# ADSP-SC83xW_HPC register map
Vendor: Analog Devices; Series: ADSP-SC83xW_HPC; File version: 3.0.3.517
CPU: 
Registers are 32-bit, read-write, reset 0x0 unless marked. A register's access mark holds for its fields unless they carry their own. Offsets are from the block's base; [hi:lo] are bit positions; {n}, {i} and the like mark numbered series.

## CGU1 — Clock Generation Unit
Base 0x3108E000
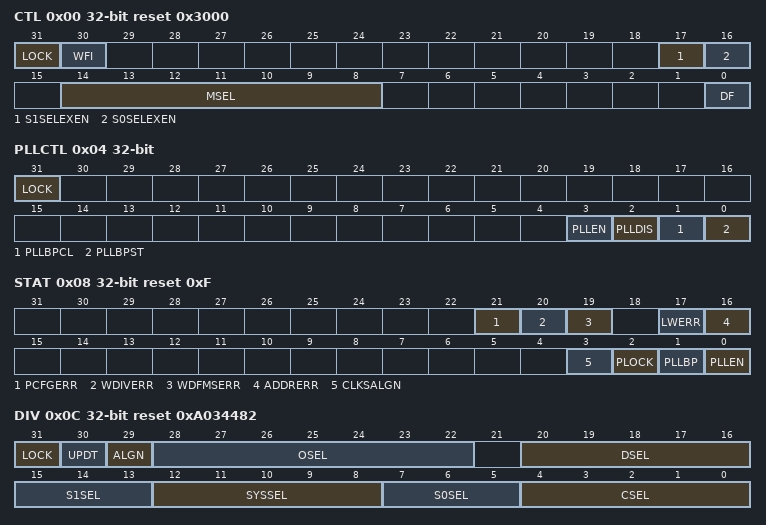
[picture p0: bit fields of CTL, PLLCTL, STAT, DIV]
0x00 CTL reset 0x3000 — Control Register
  [31] LOCK
  [30] WFI — Wait For Idle
  [17] S1SELEXEN — SCLK1 Extension Divider Enable
  [16] S0SELEXEN — SCLK0 Extension Divider Enable
  [14:8] MSEL — Multiplier Select
  [0] DF — Divide Frequency
0x04 PLLCTL — PLL Control Register
  [31] LOCK
  [3] PLLEN — PLL Enable
  [2] PLLDIS — PLL Disable
  [1] PLLBPCL — PLL Bypass Clear
  [0] PLLBPST — PLL Bypass Set
0x08 STAT reset 0xF — Status Register
  [21] PCFGERR — PLL Configuration Error
  [20] WDIVERR — Write to DIV Error
  [19] WDFMSERR — Write to MSEL Error
  [17] LWERR — Lock Write Error
  [16] ADDRERR — Address Error
  [3] CLKSALGN ro — Clock Alignment
  [2] PLOCK ro — PLL Lock
  [1] PLLBP ro — PLL Bypass
  [0] PLLEN ro — PLL Enable
0x0C DIV reset 0xA034482 — Clocks Divisor Register
  [31] LOCK
  [30] UPDT — Update Clock Divisors
  [29] ALGN — Align
  [28:22] OSEL — OCLK Divisor
  [20:16] DSEL — XCLK Divisor
  [15:13] S1SEL — SCLK 1 Divisor
  [12:8] SYSSEL — SYSCLK Divisor
  [7:5] S0SEL — SCLK 0 Divisor
  [4:0] CSEL — CCLK Divisor
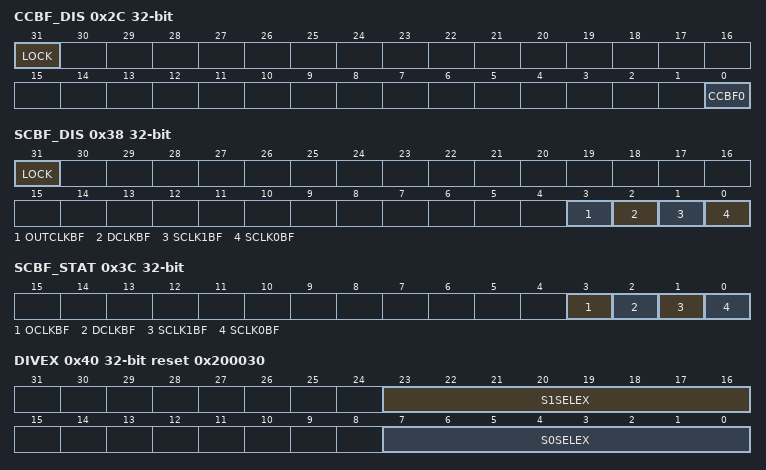
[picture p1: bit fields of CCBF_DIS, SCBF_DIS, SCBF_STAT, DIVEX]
0x2C CCBF_DIS — Core Clock Buffer Disable Register
  [31] LOCK
  [0] CCBF0 — Core Clock Buffer 0
0x30 CCBF_STAT — Core Clock Buffer Status Register
  [0] CCBF0 ro — Core Clock Buffer 0
0x38 SCBF_DIS — System Clock Buffer Disable Register
  [31] LOCK
  [3] OUTCLKBF — OCLK Buffer
  [2] DCLKBF — XCLK Buffer
  [1] SCLK1BF — SCLK1 Buffer
  [0] SCLK0BF — SCLK0 Buffer
0x3C SCBF_STAT — System Clock Buffer Status Register
  [3] OCLKBF ro — OCLK Buffer
  [2] DCLKBF ro — XCLK1 Buffer
  [1] SCLK1BF ro — SCLK1 Buffer
  [0] SCLK0BF ro — SCLK0 Buffer
0x40 DIVEX reset 0x200030 — DIV Register Extension
  [23:16] S1SELEX — SCLK 1 Extension Divisor
  [7:0] S0SELEX — SCLK 0 Extension Divisor
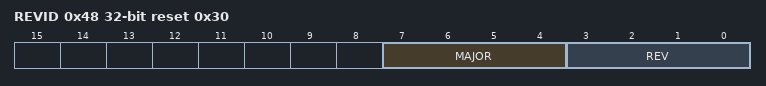
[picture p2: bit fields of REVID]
0x48 REVID reset 0x30 — Revision ID Register
  [7:4] MAJOR ro — Major Version
  [3:0] REV ro — Incremental Version ID

## CDU0 — Clock Distribution Unit
Base 0x3108F000
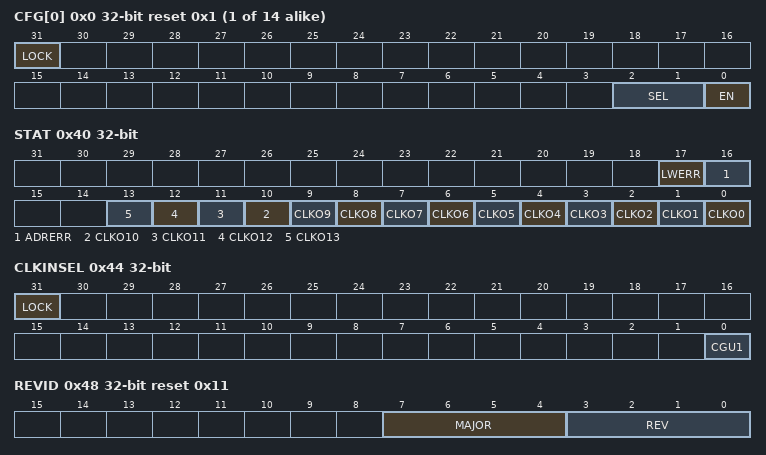
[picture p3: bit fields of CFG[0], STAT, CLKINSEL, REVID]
{0x0+4i} CFG[{i}] reset 0x1 (i=0..13) — CDU Configuration
  [31] LOCK range 0x00000000..0x00000001 — Lock Bit
  [2:1] SEL — Select Clock Input
    {v}=IN{v} (IN{v}_CLKOn Selected) (v=0..3)
  [0] EN range 0x00000000..0x00000001 — Clock Output Enabled
0x40 STAT — CDU Status
  [17] LWERR — Lock Write Error
  [16] ADRERR — Address Error
  [n] CLKO{n} ro (n=0..13) — CDU_CLKO{n} Status
0x44 CLKINSEL — CLKIN Select
  [31] LOCK range 0x00000000..0x00000001 — Lock Bit
  [0] CGU1 — CGU1 CLKINn Select
0x48 REVID reset 0x11 — CDU Revision ID
  [7:4] MAJOR ro — Major Version ID
  [3:0] REV ro — Incremental Version ID

## DPM0 — Dynamic Power Management
Base 0x31090000
0x00 CTL — Control Register
  [31] LOCK
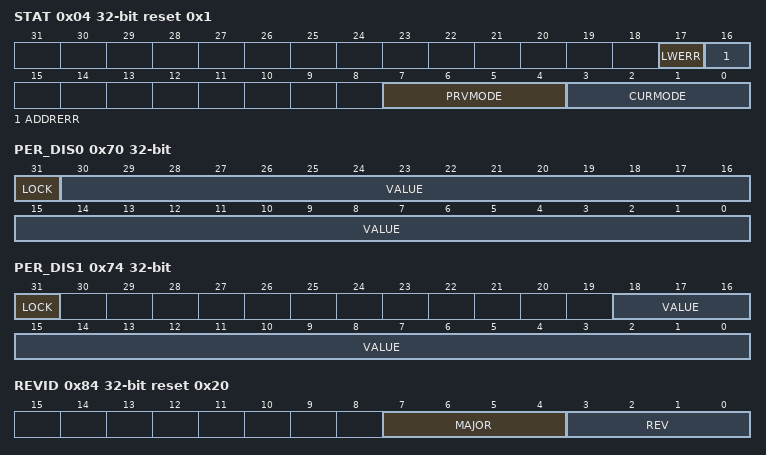
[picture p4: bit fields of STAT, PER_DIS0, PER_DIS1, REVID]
0x04 STAT reset 0x1 — Status Register
  [17] LWERR — Lock Write Error
  [16] ADDRERR — Address Error
  [7:4] PRVMODE ro — Previous Mode
  [3:0] CURMODE ro — Current Mode
0x70 PER_DIS0 — Peripherals Disable Register 0
  [31] LOCK range 0x00000000..0x00000001 — Lock Bit
  [30:0] VALUE — Peripheral Disable
0x74 PER_DIS1 — Peripherals Disable Register 1
  [31] LOCK range 0x00000000..0x00000001 — Lock Bit
  [18:0] VALUE — Peripheral Disable
0x84 REVID reset 0x20 — Revision ID
  [7:4] MAJOR ro — Major Version ID
  [3:0] REV ro — Incremental Version ID

## SWU1 — System Watchpoint Unit
Base 0x31093000
Same registers: SWU2 0x31094000, SWU3 0x31095000, SWU4 0x31096000, SWU11 0x31097000, SWU5 0x31098000, SWU13 0x3109E000, SWU12 0x310A8000, SWU7 0x31140000, SWU8 0x31141000
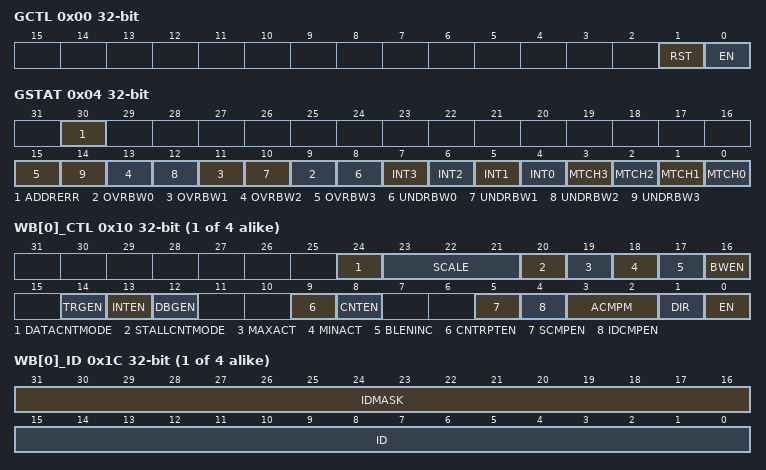
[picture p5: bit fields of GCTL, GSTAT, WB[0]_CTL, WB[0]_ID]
0x00 GCTL — Global Control Register
  [1] RST — Global Reset
  [0] EN — Global Enable
0x04 GSTAT — Global Status Register
  [30] ADDRERR — Address Error Status
  [2n+9] OVRBW{n} (n=0..3) — Group {n} Bandwidth Above Maximum Target
  [2n+8] UNDRBW{n} (n=0..3) — Group {n} Bandwidth Below Minimum Target
  [n+4] INT{n} (n=0..3) — Group {n} Interrupt Status
  [n] MTCH{n} (n=0..3) — Group {n} Match
{0x10+0x20*i} WB[{i}]_CTL (i=0..3) — Control Register n
  [24] DATACNTMODE — Data Channel Monitor
  [23:21] SCALE — Scale the number of transactions
  [20] STALLCNTMODE — Stall Count Mode
  [19] MAXACT — Action for Bandwidth Above Maximum
  [18] MINACT — Action for Bandwidth Below Minimum
  [17] BLENINC — Increment Bandwidth Count by Burst Length
  [16] BWEN — Bandwidth Mode Enable
  [14] TRGEN — Trigger Enable
  [13] INTEN — Interrupt Enable
  [12] DBGEN — Debug Event Enable
  [9] CNTRPTEN — Count Repeat Enable
  [8] CNTEN — Count Enable
  [5] SCMPEN — Secure Comparison Enable
  [4] IDCMPEN range 0x00000000..0x00000001 — ID Comparison Enable
  [3:2] ACMPM — Address Comparison Mode
  [1] DIR — Transaction Direction for Match
  [0] EN — Enable Watchpoint
{0x14+0x20*i} WB[{i}]_LA (i=0..3) — Lower Address Register n
  [31:0] ADDR range 0x00000000..0xFFFFFFFF — Lower Address
{0x18+0x20*i} WB[{i}]_UA (i=0..3) — Upper Address Register n
  [31:0] ADDR range 0x00000000..0xFFFFFFFF — Upper Address
{0x1C+0x20*i} WB[{i}]_ID (i=0..3) — ID Register n
  [31:16] IDMASK range 0x00000000..0x0000FFFF — Identity Mask (for Or with ID)
  [15:0] ID range 0x00000000..0x0000FFFF — Identity
{0x20+0x20*i} WB[{i}]_CNT (i=0..3) — Count Register n
  [15:0] COUNT range 0x00000000..0x0000FFFF
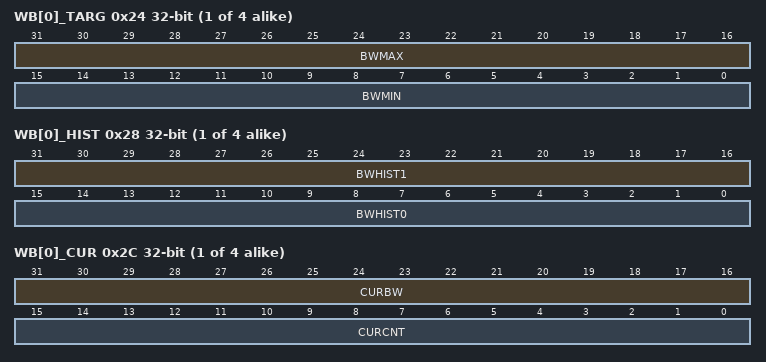
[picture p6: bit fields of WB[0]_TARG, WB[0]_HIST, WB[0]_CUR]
{0x24+0x20*i} WB[{i}]_TARG (i=0..3) — Target Register n
  [31:16] BWMAX range 0x00000000..0x0000FFFF — Maximum Bandwidth Target
  [15:0] BWMIN range 0x00000000..0x0000FFFF — Minimum Bandwidth Target
{0x28+0x20*i} WB[{i}]_HIST (i=0..3) — Bandwidth History Register n
  [31:16] BWHIST1 ro — Bandwidth from Window Before Last
  [15:0] BWHIST0 ro — Bandwidth from Last Window
{0x2C+0x20*i} WB[{i}]_CUR (i=0..3) — Current Register n
  [31:16] CURBW ro — Current Bandwidth
  [15:0] CURCNT ro — Current Count
